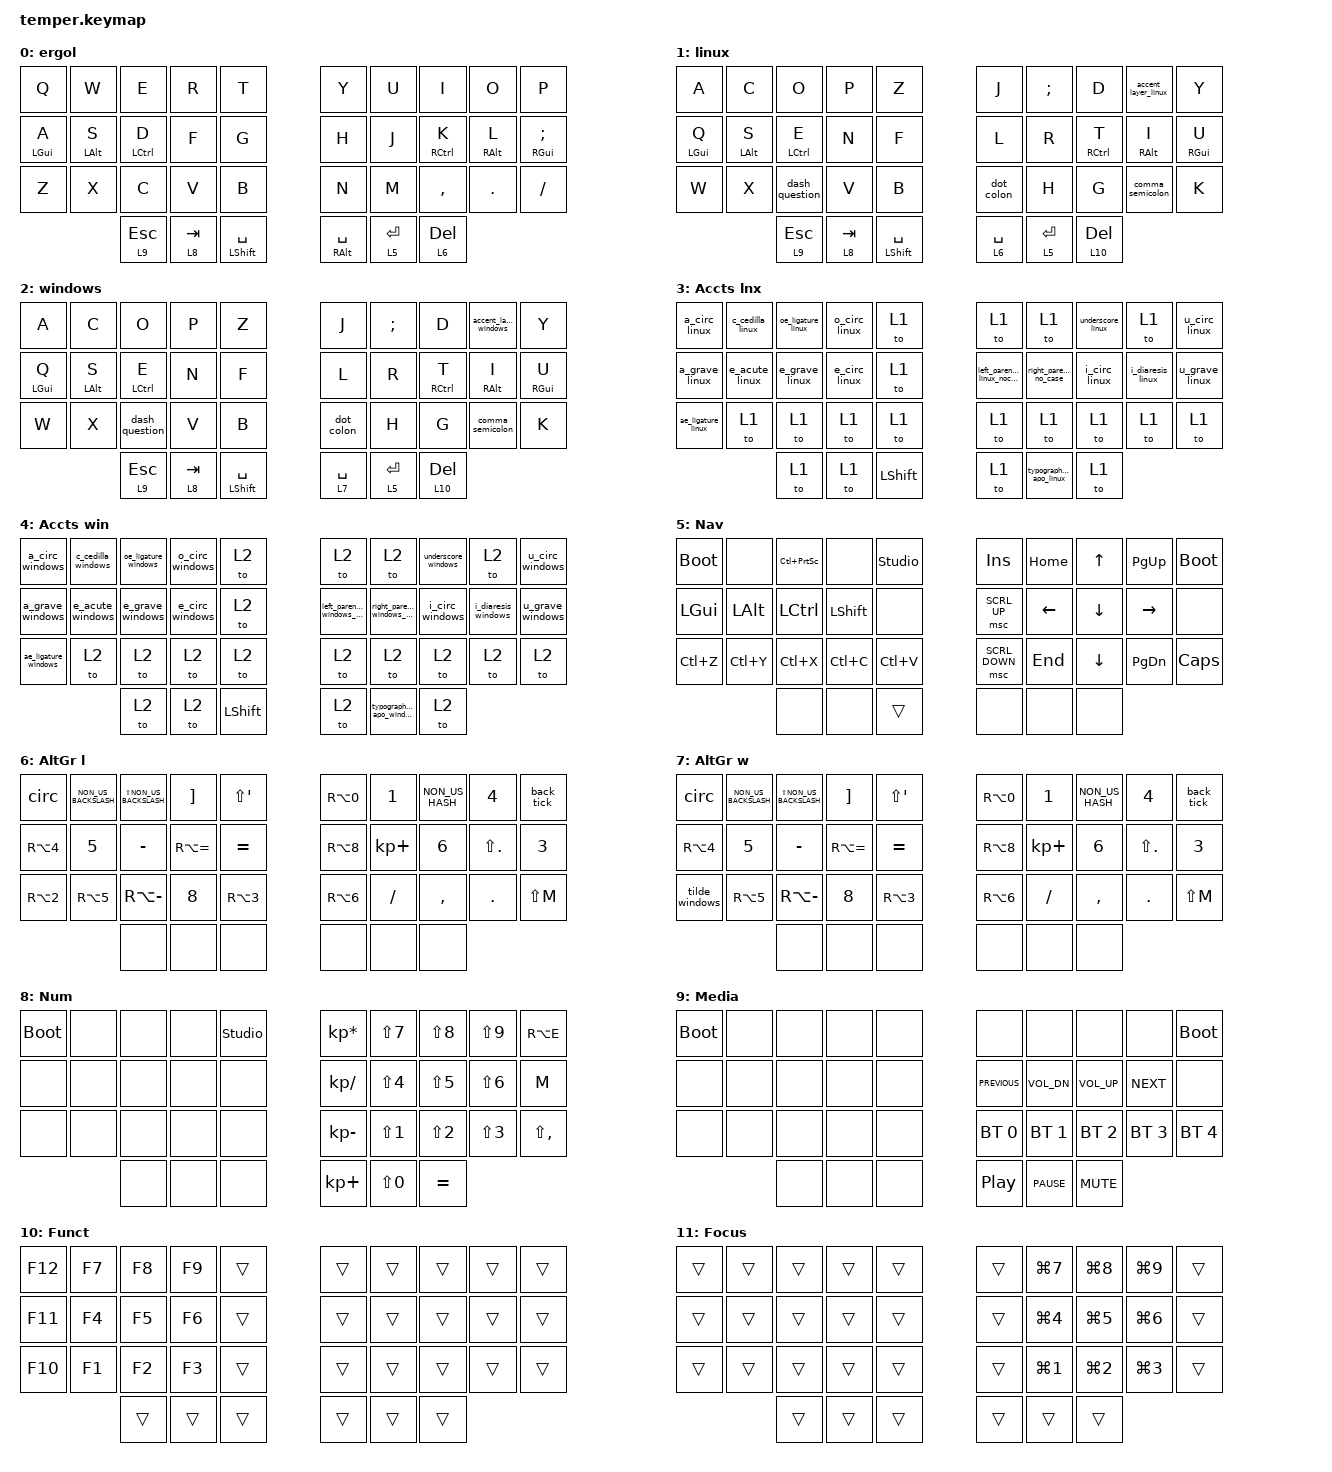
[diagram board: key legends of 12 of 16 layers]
/*
 * Copyright (c) 2020 duckyb
 *
 * SPDX-License-Identifier: MIT
 */

#include <dt-bindings/zmk/mouse.h>
#include <input/processors.dtsi>

#define ZMK_POINTING_DEFAULT_MOVE_VAL 1800  // 600, 1200
#define ZMK_MOUSE_DEFAULT_SCRL_VAL 20    // 10

#include <behaviors.dtsi>
#include <dt-bindings/zmk/bt.h>
#include <dt-bindings/zmk/keys.h>
#include <dt-bindings/zmk/pointing.h>

&mmv_input_listener {
    precisionnav {
        layers = <1>;
        input-processors = <&zip_xy_scaler 1 3>;
    };

    precisionnum {
        layers = <2>;
        input-processors = <&zip_xy_scaler 1 2>;
    };
};

&mt {
    tapping-term-ms = <150>;
    flavor = "balanced";
};

&lt { tapping-term-ms = <165>; };

/ {
    behaviors {
        mmv {
            acceleration-exponent = <2>; // 1
            time-to-max-speed-ms = <40>; // 40
            delay-ms = <0>; // 0
        };

        hm: hm {
            compatible = "zmk,behavior-hold-tap";
            label = "HM";
            bindings = <&kp>, <&kp>;

            #binding-cells = <2>;
            quick-tap-ms = <175>;
            tapping-term-ms = <280>;
            global-quick-tap;
            flavor = "balanced";
        };

        hml: hml {
            compatible = "zmk,behavior-hold-tap";
            label = "HML";
            bindings = <&kp>, <&kp>;

            #binding-cells = <2>;
            tapping-term-ms = <280>;
            quick-tap-ms = <175>;
            flavor = "balanced";
            hold-trigger-key-positions = <0 1 2 3 4 20 21 22 23 24 14 25 15 5 6 16 26 27 17 7 8 18 28 29 19 9 11 12 13>;
            require-prior-idle-ms = <150>;
            hold-trigger-on-release;
        };

        hmr: hmr {
            compatible = "zmk,behavior-hold-tap";
            label = "HMR";
            bindings = <&kp>, <&kp>;

            #binding-cells = <2>;
            tapping-term-ms = <280>;
            quick-tap-ms = <175>;
            flavor = "balanced";
            hold-trigger-key-positions = <0 10 20 21 1 11 12 2 3 4 24 14 13 23 22 25 26 28 27 29 9 8 7 6 5 15 16 17 18 30 31 32 33 34 35>;
            require-prior-idle-ms = <150>;
            hold-trigger-on-release;
        };

        mo_tog: mo_tog {
            compatible = "zmk,behavior-hold-tap";
            label = "MO_TOG";
            bindings = <&mo>, <&tog>;

            #binding-cells = <2>;
            tapping-term-ms = <200>;
            quick-tap-ms = <180>;
        };

        space_alt: space_alt {
            compatible = "zmk,behavior-hold-tap";
            label = "SPACE_ALT";
            bindings = <&kp>, <&kp>;

            #binding-cells = <2>;
            tapping-term-ms = <235>;
            quick-tap-ms = <100>;
            flavor = "tap-preferred";
            hold-trigger-key-positions = <10 12 20 21 16 17 19 6>;
            hold-trigger-on-release;
        };

        dot_colon: dot_colon {
            compatible = "zmk,behavior-mod-morph";
            label = "DOT_COLON";
            bindings = <&kp LS(COMMA)>, <&kp DOT>;

            #binding-cells = <0>;
            mods = <(MOD_LSFT|MOD_RSFT)>;
        };

        comma_semicolon: comma_semicolon {
            compatible = "zmk,behavior-mod-morph";
            label = "COMMA_SEMICOLON";
            bindings = <&kp M>, <&kp COMMA>;

            #binding-cells = <0>;
            mods = <(MOD_LSFT|MOD_RSFT)>;
        };

        a_circ_linux: a_circ_linux {
            compatible = "zmk,behavior-mod-morph";
            label = "A_CIRC_LINUX";
            bindings = <&a_circ_linux_lower>, <&a_circ_linux_upper>;

            #binding-cells = <0>;
            mods = <(MOD_LSFT|MOD_RSFT)>;
        };

        c_cedilla_linux: c_cedilla_linux {
            compatible = "zmk,behavior-mod-morph";
            label = "C_CEDILLA_LINUX";
            bindings = <&c_cedilla_linux_lower>, <&c_cedilla_linux_upper>;

            #binding-cells = <0>;
            mods = <(MOD_LSFT|MOD_RSFT)>;
        };

        oe_ligature_linux: oe_ligature_linux {
            compatible = "zmk,behavior-mod-morph";
            label = "OE_LIGATURE_LINUX";
            bindings = <&oe_ligature_linux_lower>, <&oe_ligature_linux_upper>;

            #binding-cells = <0>;
            mods = <(MOD_LSFT|MOD_RSFT)>;
        };

        o_circ_linux: o_circ_linux {
            compatible = "zmk,behavior-mod-morph";
            label = "O_CIRC_LINUX";
            bindings = <&o_circ_lower_linux>, <&o_circ_upper_linux>;

            #binding-cells = <0>;
            mods = <(MOD_LSFT|MOD_RSFT)>;
        };

        a_grave_linux: a_grave_linux {
            compatible = "zmk,behavior-mod-morph";
            label = "A_GRAVE_LINUX";
            bindings = <&a_grave_lower_linux>, <&a_grave_upper_linux>;

            #binding-cells = <0>;
            mods = <(MOD_LSFT|MOD_RSFT)>;
        };

        e_acute_linux: e_acute_linux {
            compatible = "zmk,behavior-mod-morph";
            label = "E_ACUTE_LINUX";
            bindings = <&e_acute_lower_linux>, <&e_acute_upper_linux>;

            #binding-cells = <0>;
            mods = <(MOD_LSFT|MOD_RSFT)>;
        };

        e_grave_linux: e_grave_linux {
            compatible = "zmk,behavior-mod-morph";
            label = "E_GRAVE_LINUX";
            bindings = <&e_grave_lower_linux>, <&e_grave_upper_linux>;

            #binding-cells = <0>;
            mods = <(MOD_LSFT|MOD_RSFT)>;
        };

        e_circ_linux: e_circ_linux {
            compatible = "zmk,behavior-mod-morph";
            label = "E_CIRC_LINUX";
            bindings = <&e_circ_lower_linux>, <&e_circ_upper_linux>;

            #binding-cells = <0>;
            mods = <(MOD_LSFT|MOD_RSFT)>;
        };

        o_circ_windows: o_circ_windows {
            compatible = "zmk,behavior-mod-morph";
            label = "O_CIRC_WINDOWS";
            bindings = <&o_circ_lower_windows>, <&o_circ_upper_windows>;

            #binding-cells = <0>;
            mods = <(MOD_LSFT|MOD_RSFT)>;
        };

        dash_question: dash_question {
            compatible = "zmk,behavior-mod-morph";
            label = "DASH_QUESTION";
            bindings = <&kp NUMBER_6>, <&kp LS(M)>;

            #binding-cells = <0>;
            mods = <(MOD_LSFT|MOD_RSFT)>;
        };

        a_circ_windows: a_circ_windows {
            compatible = "zmk,behavior-mod-morph";
            label = "A_CIRC_WINDOWS";
            bindings = <&a_circ_windows_lower>, <&a_circ_windows_upper>;

            #binding-cells = <0>;
            mods = <(MOD_LSFT|MOD_RSFT)>;
        };

        c_cedilla_windows: c_cedilla_windows {
            compatible = "zmk,behavior-mod-morph";
            label = "C_CEDILLA_WINDOWS";
            bindings = <&c_cedila_lower_windows>, <&c_cedilla_upper_windows>;

            #binding-cells = <0>;
            mods = <(MOD_LSFT|MOD_RSFT)>;
        };

        a_grave_windows: a_grave_windows {
            compatible = "zmk,behavior-mod-morph";
            label = "A_GRAVE_WINDOWS";
            bindings = <&a_grave_lower_windows>, <&a_grave_upper_windows>;

            #binding-cells = <0>;
            mods = <(MOD_LSFT|MOD_RSFT)>;
        };

        e_acute_windows: e_acute_windows {
            compatible = "zmk,behavior-mod-morph";
            label = "E_ACUTE_WINDOWS";
            bindings = <&e_acute_lower_windows>, <&e_acute_upper_windows>;

            #binding-cells = <0>;
            mods = <(MOD_LSFT|MOD_RSFT)>;
        };

        e_grave_windows: e_grave_windows {
            compatible = "zmk,behavior-mod-morph";
            label = "E_GRAVE_WINDOWS";
            bindings = <&e_grave_lower_windows>, <&e_grave_upper_windows>;

            #binding-cells = <0>;
            mods = <(MOD_LSFT|MOD_RSFT)>;
        };

        u_grave_windows: u_grave_windows {
            compatible = "zmk,behavior-mod-morph";
            label = "U_GRAVE_WINDOWS";
            bindings = <&u_grave_lower_windows>, <&u_grave_upper_windows>;

            #binding-cells = <0>;
            mods = <(MOD_LSFT|MOD_RSFT)>;
        };

        accent_layer_linux: accent_layer_linux {
            compatible = "zmk,behavior-mod-morph";
            label = "ACCENT_LAYER_LINUX";
            bindings = <&to 3>, <&kp SLASH>;

            #binding-cells = <0>;
            mods = <(MOD_LSFT|MOD_RSFT)>;
        };

        accent_layer_windows: accent_layer_windows {
            compatible = "zmk,behavior-mod-morph";
            label = "ACCENT_LAYER_WINDOWS";
            bindings = <&to 4>, <&kp SLASH>;

            #binding-cells = <0>;
            mods = <(MOD_LSFT|MOD_RSFT)>;
        };

        ae_ligature_linux: ae_ligature_linux {
            compatible = "zmk,behavior-mod-morph";
            label = "AE_LIGATURE_LINUX";
            bindings = <&ae_ligature_linux_lower>, <&ae_ligature_linux_upper>;

            #binding-cells = <0>;
            mods = <(MOD_LSFT|MOD_RCTL)>;
        };

        u_grave_linux: u_grave_linux {
            compatible = "zmk,behavior-mod-morph";
            label = "U_GRAVE_LINUX";
            bindings = <&u_grave_lower_linux>, <&u_grave_upper_linux>;

            #binding-cells = <0>;
            mods = <(MOD_LSFT|MOD_RSFT)>;
        };

        u_circ_linux: u_circ_linux {
            compatible = "zmk,behavior-mod-morph";
            label = "U_CIRC_LINUX";
            bindings = <&u_circ_lower_linux>, <&u_circ_upper_linux>;

            #binding-cells = <0>;
            mods = <(MOD_LSFT|MOD_RSFT)>;
        };

        left_parenthesis_linux_nocase: left_parenthesis_linux_nocase {
            compatible = "zmk,behavior-mod-morph";
            label = "LEFT_PARENTHESIS_LINUX_NOCASE";
            bindings = <&left_parenthesis_linux>, <&left_parenthesis_linux>;

            #binding-cells = <0>;
            mods = <(MOD_LSFT|MOD_RSFT)>;
        };

        right_parenthesis_no_case: right_parenthesis_no_case {
            compatible = "zmk,behavior-mod-morph";
            label = "RIGHT_PARENTHESIS_NO_CASE";
            bindings = <&right_parenthesis_linux>, <&right_parenthesis_linux>;

            #binding-cells = <0>;
            mods = <(MOD_LSFT|MOD_RSFT)>;
        };

        i_circ_linux: i_circ_linux {
            compatible = "zmk,behavior-mod-morph";
            label = "I_CIRC_LINUX";
            bindings = <&i_circ_lower_linux>, <&i_circ_upper_linux>;

            #binding-cells = <0>;
            mods = <(MOD_LSFT|MOD_RSFT)>;
        };

        i_diaresis_linux: i_diaresis_linux {
            compatible = "zmk,behavior-mod-morph";
            label = "I_DIARESIS_LINUX";
            bindings = <&i_diaresis_lower_linux>, <&i_diaresis_upper_linux>;

            #binding-cells = <0>;
            mods = <(MOD_LSFT|MOD_RSFT)>;
        };

        u_circ_windows: u_circ_windows {
            compatible = "zmk,behavior-mod-morph";
            label = "U_CIRC_WINDOWS";
            bindings = <&u_circ_lower_windows>, <&u_circ_upper_windows>;

            #binding-cells = <0>;
            mods = <(MOD_LSFT|MOD_RSFT)>;
        };

        i_diaresis_windows: i_diaresis_windows {
            compatible = "zmk,behavior-mod-morph";
            label = "I_DIARESIS_WINDOWS";
            bindings = <&i_diaresis_lower_windows>, <&i_diaresis_upper_windows>;

            #binding-cells = <0>;
            mods = <(MOD_LSFT|MOD_RSFT)>;
        };

        i_circ_windows: i_circ_windows {
            compatible = "zmk,behavior-mod-morph";
            label = "I_CIRC_WINDOWS";
            bindings = <&i_circ_lower_windows>, <&i_circ_upper_windows>;

            #binding-cells = <0>;
            mods = <(MOD_LSFT|MOD_RSFT)>;
        };

        left_parenthesis_windows_nocase: left_parenthesis_windows_nocase {
            compatible = "zmk,behavior-mod-morph";
            label = "LEFT_PARENTHESIS_WINDOWS_NOCASE";
            bindings = <&left_parenthesis_windows>, <&left_parenthesis_windows>;

            #binding-cells = <0>;
            mods = <(MOD_LSFT|MOD_RSFT)>;
        };

        right_parenthesis_windows_nocas: right_parenthesis_windows_nocas {
            compatible = "zmk,behavior-mod-morph";
            label = "RIGHT_PARENTHESIS_WINDOWS_NOCAS";
            bindings =
                <&right_parenthesis_windows>,
                <&right_parenthesis_windows>;

            #binding-cells = <0>;
            mods = <(MOD_LSFT|MOD_RSFT)>;
        };

        oe_ligature_windows: oe_ligature_windows {
            compatible = "zmk,behavior-mod-morph";
            label = "OE_LIGATURE_WINDOWS";
            bindings =
                <&oe_ligature_windows_lower>,
                <&oe_ligature_upper_windows>;

            #binding-cells = <0>;
            mods = <(MOD_LSFT|MOD_RSFT)>;
        };

        e_circ_windows: e_circ_windows {
            compatible = "zmk,behavior-mod-morph";
            label = "E_CIRC_WINDOWS";
            bindings = <&e_circ_lower_windows>, <&e_circ_upper_windows>;

            #binding-cells = <0>;
            mods = <(MOD_LSFT|MOD_RSFT)>;
        };

        ae_ligature_windows: ae_ligature_windows {
            compatible = "zmk,behavior-mod-morph";
            label = "AE_LIGATURE_WINDOWS";
            bindings =
                <&ae_ligature_windows_lower>,
                <&ae_ligature_upper_windows>;

            #binding-cells = <0>;
            mods = <(MOD_LSFT|MOD_RSFT)>;
        };
    };

    combos {
        compatible = "zmk,combos";

        Cut {
            bindings = <&kp LC(X)>;
            key-positions = <21 22>;
            layers = <1 0 2>;
        };

        Copy {
            bindings = <&kp LC(C)>;
            key-positions = <22 23>;
            layers = <1>;
        };

        Paste {
            bindings = <&kp LC(V)>;
            key-positions = <23 24>;
            layers = <1>;
        };

        screenshot {
            bindings = <&kp LC(PRINTSCREEN)>;
            key-positions = <9 8>;
            layers = <1 0 2>;
        };

        boot_l {
            bindings = <&bootloader>;
            key-positions = <0 4 32>;
            layers = <1>;
        };

        win_nav_left {
            bindings = <&kp LG(LEFT)>;
            key-positions = <16 17>;
            layers = <11>;
        };

        win_nav_right {
            bindings = <&kp LG(RIGHT)>;
            key-positions = <19 18>;
            layers = <11>;
        };

        win_nav_up {
            bindings = <&kp LG(UP_ARROW)>;
            key-positions = <7 8>;
            layers = <11>;
        };

        win_nav_down {
            bindings = <&kp LG(DOWN_ARROW)>;
            key-positions = <17 18>;
            layers = <11>;
        };

        win_nav_left_shift {
            bindings = <&kp LG(LS(LEFT))>;
            key-positions = <16 17 18>;
            layers = <11>;
        };

        win_nav_right_shift {
            bindings = <&kp LG(LS(RIGHT))>;
            key-positions = <19 18 17>;
            layers = <11>;
        };

        mouse_layer_switch {
            bindings = <&tog 12>;
            key-positions = <14 15>;
            timeout-ms = <175>;
        };

        linux_to_windows {
            bindings = <&to 2>;
            key-positions = <34 35>;
            layers = <1>;
        };

        windows_to_ergol {
            bindings = <&to 0>;
            key-positions = <34 35>;
            layers = <2>;
        };

        ergol_to_linux {
            bindings = <&to 1>;
            key-positions = <34 35>;
            layers = <0>;
        };

        windows_focus {
            bindings = <&mo 11>;
            key-positions = <31 32>;
            layers = <2 1 0>;
        };

        paste_with_mouse {
            bindings = <&shift_right_click>;
            key-positions = <5 6>;
        };

        backspace_combo {
            bindings = <&kp BACKSPACE>;
            key-positions = <6 7>;
            layers = <0 2 1>;
        };

        Tmux_layer {
            bindings = <&mo 13>;
            key-positions = <30 31>;
        };

        vi_layer {
            bindings = <&mo 15>;
            key-positions = <30 32>;
            layers = <0 2 1>;
        };
    };

    macros {
        a_circ_linux_lower: a_circ_linux_lower {
            compatible = "zmk,behavior-macro";
            #binding-cells = <0>;
            bindings = <&kp RA(Q) &to 1>;
            label = "A_CIRC_LINUX_LOWER";
        };

        a_circ_linux_upper: a_circ_linux_upper {
            compatible = "zmk,behavior-macro";
            #binding-cells = <0>;
            bindings = <&kp RA(A) &to 1>;
            label = "A_CIRC_LINUX_UPPER";
        };

        c_cedilla_linux_lower: c_cedilla_linux_lower {
            compatible = "zmk,behavior-macro";
            #binding-cells = <0>;
            bindings = <&kp RA(R) &to 1>;
            label = "C_CEDILLA_LINUX_LOWER";
        };

        c_cedilla_linux_upper: c_cedilla_linux_upper {
            compatible = "zmk,behavior-macro";
            #binding-cells = <0>;
            bindings = <&kp RA(LS(R)) &to 1>;
            label = "C_CEDILLA_LINUX_UPPER";
        };

        oe_ligature_linux_lower: oe_ligature_linux {
            compatible = "zmk,behavior-macro";
            #binding-cells = <0>;
            bindings = <&kp GRAVE &to 1>;
            label = "OE_LIGATURE_LINUX_LOWER";
        };

        oe_ligature_linux_upper: oe_ligature_linux_upper {
            compatible = "zmk,behavior-macro";
            #binding-cells = <0>;
            bindings = <&kp LS(GRAVE) &to 1>;
            label = "OE_LIGATURE_LINUX_UPPER";
        };

        o_circ_lower_linux: o_circ_lower_linux {
            compatible = "zmk,behavior-macro";
            #binding-cells = <0>;
            bindings = <&kp LEFT_BRACKET &kp O &to 1>;
            label = "O_CIRC_LOWER_LINUX";
        };

        o_circ_upper_linux: o_circ_upper_linux {
            compatible = "zmk,behavior-macro";
            #binding-cells = <0>;
            bindings = <&kp LEFT_BRACKET &kp LS(O) &to 1>;
            label = "O_CIRC_UPPER_LINUX";
        };

        a_grave_lower_linux: a_grave_lower_linux {
            compatible = "zmk,behavior-macro";
            #binding-cells = <0>;
            bindings = <&kp N0 &to 1>;
            label = "A_GRAVE_LOWER_LINUX";
        };

        a_grave_upper_linux: a_grave_upper_linux {
            compatible = "zmk,behavior-macro";
            #binding-cells = <0>;
            bindings = <&kp RA(N7) &kp LS(Q) &to 1>;
            label = "A_GRAVE_UPPER_LINUX";
        };

        e_acute_lower_linux: e_acute_lower_linux {
            compatible = "zmk,behavior-macro";
            #binding-cells = <0>;
            bindings = <&kp NUMBER_2 &to 1>;
            label = "E_ACUTE_LOWER_LINUX";
        };

        e_acute_upper_linux: e_acute_upper_linux {
            compatible = "zmk,behavior-macro";
            #binding-cells = <0>;
            bindings = <&kp LC(LS(U)) &kp N0 &kp N0 &kp C &kp N9 &kp ENTER &to 1>;
            label = "E_ACUTE_UPPER_LINUX";
        };

        e_grave_lower_linux: e_grave_lower_linux {
            compatible = "zmk,behavior-macro";
            #binding-cells = <0>;
            bindings = <&kp NUMBER_7 &to 1>;
            label = "E_GRAVE_LOWER_LINUX";
        };

        e_grave_upper_linux: e_grave_upper_linux {
            compatible = "zmk,behavior-macro";
            #binding-cells = <0>;
            bindings = <&kp RA(RS(NUMBER_7)) &to 1>;
            label = "E_GRAVE_UPPER_LINUX";
        };

        e_circ_lower_linux: e_circ_lower_linux {
            compatible = "zmk,behavior-macro";
            #binding-cells = <0>;
            bindings = <&kp RA(RIGHT_BRACKET) &to 1>;
            label = "E_CIRC_LOWER_LINUX";
        };

        e_circ_upper_linux: e_circ_upper_linux {
            compatible = "zmk,behavior-macro";
            #binding-cells = <0>;
            bindings = <&kp RA(D) &to 1>;
            label = "E_CIRC_UPPER_LINUX";
        };

        a_circ_windows_lower: a_circ {
            compatible = "zmk,behavior-macro";
            #binding-cells = <0>;
            bindings = <&kp LEFT_BRACKET &kp Q &to 2>;
            label = "A_CIRC";
        };

        o_circ_lower_windows: o_circ {
            compatible = "zmk,behavior-macro";
            #binding-cells = <0>;
            bindings = <&kp LEFT_BRACKET &kp O &to 2>;
            label = "O_CIRC";
        };

        e_circ_lower_windows: e_circ_lower_windows {
            compatible = "zmk,behavior-macro";
            #binding-cells = <0>;
            bindings = <&kp LEFT_BRACKET &kp E &to 2>;
            label = "E_CIRC_LOWER_WINDOWS";
        };

        ae_ligature_linux_lower: ae_ligature {
            compatible = "zmk,behavior-macro";
            #binding-cells = <0>;
            bindings = <&kp RA(G) &to 1>;
            label = "AE_LIGATURE";
        };

        i_circ_lower_windows: i_circ {
            compatible = "zmk,behavior-macro";
            #binding-cells = <0>;
            bindings = <&kp LEFT_BRACKET &kp I &to 2>;
            label = "I_CIRC";
        };

        i_diaresis_lower_windows: i_diaresis {
            compatible = "zmk,behavior-macro";
            #binding-cells = <0>;
            bindings = <&kp LS(LEFT_BRACKET) &kp I &to 2>;
            label = "I_DIARESIS";
        };

        u_circ_lower_windows: u_circ {
            compatible = "zmk,behavior-macro";
            #binding-cells = <0>;
            bindings = <&kp LEFT_BRACKET &kp U &to 2>;
            label = "U_CIRC";
        };

        o_circ_upper_windows: o_circ_maj {
            compatible = "zmk,behavior-macro";
            #binding-cells = <0>;
            bindings = <&kp LEFT_BRACKET &kp LS(O) &to 2>;
            label = "O_CIRC_MAJ";
        };

        circ: circ {
            compatible = "zmk,behavior-macro";
            #binding-cells = <0>;
            bindings = <&kp RA(N9)>;
            label = "CIRC";
        };

        back_tick: back_tick {
            compatible = "zmk,behavior-macro";
            #binding-cells = <0>;
            bindings = <&kp RA(N7) &kp SPACE>;
            label = "BACK_TICK";
        };

        oe_ligature_windows_lower: oe_ligature_windows {
            compatible = "zmk,behavior-macro";
            #binding-cells = <0>;
            bindings = <&kt LEFT_ALT &kp KP_NUMBER_0 &kp KP_N1 &kp KP_N5 &kp KP_N6 &kt LEFT_ALT &to 2>;
            label = "OE_LIGATURE_WINDOWS";
        };

        tilde_windows: tilde_windows {
            compatible = "zmk,behavior-macro";
            #binding-cells = <0>;
            bindings = <&kp RA(NUMBER_2) &kp SPACE>;
            label = "TILDE_WINDOWS";
        };

        ae_ligature_windows_lower: ae_ligature_windows_lower {
            compatible = "zmk,behavior-macro";
            #binding-cells = <0>;
            bindings = <&kt LEFT_ALT &kp KP_N0 &kp KP_N2 &kp KP_N3 &kp KP_N0 &kt LEFT_ALT &to 2>;
            label = "AE_LIGATURE_WINDOWS_LOWER";
        };

        a_circ_windows_upper: a_circ_windows_maj {
            compatible = "zmk,behavior-macro";
            #binding-cells = <0>;
            bindings = <&kp LEFT_BRACKET &kp LS(Q) &to 2>;
            label = "A_CIRC_WINDOWS_MAJ";
        };

        c_cedilla_upper_windows: c_cedilla_maj_windows {
            compatible = "zmk,behavior-macro";
            #binding-cells = <0>;
            bindings = <&kt LEFT_ALT &kp KP_N0 &kp KP_N1 &kp KP_N9 &kp KP_N9 &kt LEFT_ALT &to 2>;
            label = "C_CEDILLA_MAJ_WINDOWS";
        };

        a_grave_lower_windows: a_grave_lower_windows {
            compatible = "zmk,behavior-macro";
            #binding-cells = <0>;
            bindings = <&kp N0 &to 2>;
            label = "A_GRAVE_LOWER_WINDOWS";
        };

        e_acute_upper_windows: e_acute_upper_windows {
            compatible = "zmk,behavior-macro";
            #binding-cells = <0>;
            bindings = <&kt LEFT_ALT &kp KP_N0 &kp KP_N2 &kp KP_N0 &kp KP_N1 &kt LEFT_ALT &to 2>;
            label = "E_ACUTE_UPPER_WINDOWS";
        };

        e_grave_upper_windows: e_grave_upper_windows {
            compatible = "zmk,behavior-macro";
            #binding-cells = <0>;
            bindings = <&kp RA(N7) &kp LS(E) &to 2>;
            label = "E_GRAVE_UPPER_WINDOWS";
        };

        u_grave_upper_windows: u_grave_upper_windows {
            compatible = "zmk,behavior-macro";
            #binding-cells = <0>;
            bindings = <&kp RA(N7) &kp LS(U) &to 2>;
            label = "U_GRAVE_UPPER_WINDOWS";
        };

        typographical_apo_linux: typographical_apo_linux {
            compatible = "zmk,behavior-macro";
            #binding-cells = <0>;
            bindings = <&kp LS(LC(U)) &kp KP_N2 &kp KP_N0 &kp KP_N1 &kp KP_N9 &kp ENTER &to 1>;
            label = "TYPOGRAPHICAL_APO_LINUX";
        };

        typographical_apo_windows: typographical_apo_windows {
            compatible = "zmk,behavior-macro";
            #binding-cells = <0>;
            bindings = <&kt LEFT_ALT &kp KP_N0 &kp KP_N1 &kp KP_N4 &kp KP_N6 &kt LEFT_ALT &to 2>;
            label = "TYPOGRAPHICAL_APO_WINDOWS";
        };

        ae_ligature_linux_upper: ae_ligature_upper_linux {
            compatible = "zmk,behavior-macro";
            #binding-cells = <0>;
            bindings = <&kp RA(G) &to 1>;
            label = "AE_LIGATURE_UPPER_LINUX";
        };

        underscore_linux: underscore_linux {
            compatible = "zmk,behavior-macro";
            #binding-cells = <0>;
            bindings = <&kp N8 &to 1>;
            label = "UNDERSCORE_LINUX";
        };

        u_grave_upper_linux: u_grave_upper_linux {
            compatible = "zmk,behavior-macro";
            #binding-cells = <0>;
            bindings = <&kp RA(N7) &kp LS(U) &to 1>;
            label = "U_GRAVE_UPPER_LINUX";
        };

        u_grave_lower_linux: u_grave_lower_linux {
            compatible = "zmk,behavior-macro";
            #binding-cells = <0>;
            bindings = <&kp RA(N7) &kp U &to 1>;
            label = "U_GRAVE_LOWER_LINUX";
        };

        u_circ_lower_linux: u_circ_linux_lower {
            compatible = "zmk,behavior-macro";
            #binding-cells = <0>;
            bindings = <&kp LEFT_BRACKET &kp U &to 1>;
            label = "U_CIRC_LINUX_LOWER";
        };

        u_circ_upper_linux: u_circ_upper_linux {
            compatible = "zmk,behavior-macro";
            #binding-cells = <0>;
            bindings = <&kp LEFT_BRACKET &kp LS(U) &to 1>;
            label = "U_CIRC_UPPER_LINUX";
        };

        left_parenthesis_linux: left_parenthesis_linux {
            compatible = "zmk,behavior-macro";
            #binding-cells = <0>;
            bindings = <&kp N5 &to 1>;
            label = "LEFT_PARENTHESIS_LINUX";
        };

        right_parenthesis_linux: right_parenthesis_linux {
            compatible = "zmk,behavior-macro";
            #binding-cells = <0>;
            bindings = <&kp MINUS &to 1>;
            label = "RIGHT_PARENTHESIS_LINUX";
        };

        i_circ_lower_linux: i_circ_lower_linux {
            compatible = "zmk,behavior-macro";
            #binding-cells = <0>;
            bindings = <&kp LEFT_BRACKET &kp I &to 1>;
            label = "I_CIRC_LOWER_LINUX";
        };

        i_circ_upper_linux: i_circ_upper_linux {
            compatible = "zmk,behavior-macro";
            #binding-cells = <0>;
            bindings = <&kp LEFT_BRACKET &kp LS(I) &to 1>;
            label = "I_CIRC_UPPER_LINUX";
        };

        i_diaresis_lower_linux: i_diaresis_lower_linux {
            compatible = "zmk,behavior-macro";
            #binding-cells = <0>;
            bindings = <&kp LS(LEFT_BRACKET) &kp I &to 1>;
            label = "I_DIARESIS_LOWER_LINUX";
        };

        i_diaresis_upper_linux: i_diaresis_upper_linux {
            compatible = "zmk,behavior-macro";
            #binding-cells = <0>;
            bindings = <&kp LS(LEFT_BRACKET) &kp LS(I) &to 1>;
            label = "I_DIARESIS_UPPER_LINUX";
        };

        underscore_windows: underscore_windows {
            compatible = "zmk,behavior-macro";
            #binding-cells = <0>;
            bindings = <&kp N8 &to 2>;
            label = "UNDERSCORE_WINDOWS";
        };

        u_circ_upper_windows: u_circ_upper_windows {
            compatible = "zmk,behavior-macro";
            #binding-cells = <0>;
            bindings = <&kp LEFT_BRACKET &kp LS(U) &to 2>;
            label = "U_CIRC_UPPER_WINDOWS";
        };

        u_grave_lower_windows: u_grave_lower_windows {
            compatible = "zmk,behavior-macro";
            #binding-cells = <0>;
            bindings = <&kp RA(N7) &kp U &to 2>;
            label = "U_GRAVE_LOWER_WINDOWS";
        };

        i_diaresis_upper_windows: i_diaresis_upper_windows {
            compatible = "zmk,behavior-macro";
            #binding-cells = <0>;
            bindings = <&kp LS(LEFT_BRACKET) &kp LS(I) &to 2>;
            label = "I_DIARESIS_UPPER_WINDOWS";
        };

        i_circ_upper_windows: i_circ_upper_windows {
            compatible = "zmk,behavior-macro";
            #binding-cells = <0>;
            bindings = <&kp LEFT_BRACKET &kp LS(I) &to 2>;
            label = "I_CIRC_UPPER_WINDOWS";
        };

        left_parenthesis_windows: left_parenthesis_windows {
            compatible = "zmk,behavior-macro";
            #binding-cells = <0>;
            bindings = <&kp N5 &to 2>;
            label = "LEFT_PARENTHESIS_WINDOWS";
        };

        right_parenthesis_windows: right_parenthesis_windows {
            compatible = "zmk,behavior-macro";
            #binding-cells = <0>;
            bindings = <&kp MINUS &to 2>;
            label = "RIGHT_PARENTHESIS_WINDOWS";
        };

        oe_ligature_upper_windows: oe_ligature_upper_windows {
            compatible = "zmk,behavior-macro";
            #binding-cells = <0>;
            bindings = <&kt LEFT_ALT &kp KP_NUMBER_0 &kp KP_N1 &kp KP_N4 &kp KP_N0 &kt LEFT_ALT &to 2>;
            label = "OE_LIGATURE_UPPER_WINDOWS";
        };

        c_cedila_lower_windows: c_cedila_lower_windows {
            compatible = "zmk,behavior-macro";
            #binding-cells = <0>;
            bindings = <&kp N9 &to 2>;
            label = "C_CEDILA_LOWER_WINDOWS";
        };

        a_grave_upper_windows: a_grave_upper_windows {
            compatible = "zmk,behavior-macro";
            #binding-cells = <0>;
            bindings = <&kp RA(N7) &kp LS(Q) &to 2>;
            label = "A_GRAVE_UPPER_WINDOWS";
        };

        e_acute_lower_windows: e_acute_lower_windows {
            compatible = "zmk,behavior-macro";
            #binding-cells = <0>;
            bindings = <&kp N2 &to 2>;
            label = "E_ACUTE_LOWER_WINDOWS";
        };

        e_grave_lower_windows: e_grave_lower_windows {
            compatible = "zmk,behavior-macro";
            #binding-cells = <0>;
            bindings = <&kp N7 &to 2>;
            label = "E_GRAVE_LOWER_WINDOWS";
        };

        e_circ_upper_windows: e_circ_upper_windows {
            compatible = "zmk,behavior-macro";
            #binding-cells = <0>;
            bindings = <&kp LEFT_BRACKET &kp LS(E) &to 2>;
            label = "E_CIRC_UPPER_WINDOWS";
        };

        ae_ligature_upper_windows: ae_ligature_upper_windows {
            compatible = "zmk,behavior-macro";
            #binding-cells = <0>;
            bindings = <&kt LEFT_ALT &kp KP_N0 &kp KP_N1 &kp KP_N9 &kp KP_N8 &kt LEFT_ALT &to 2>;
            label = "AE_LIGATURE_UPPER_WINDOWS";
        };

        shift_right_click: shift_right_click {
            compatible = "zmk,behavior-macro";
            #binding-cells = <0>;
            bindings = <&kt LEFT_SHIFT &mkp RCLK &kt LEFT_SHIFT>;
            label = "SHIFT_RIGHT_CLICK";
        };

        tmux_new_pane: tmux_new_pane {
            compatible = "zmk,behavior-macro";
            #binding-cells = <0>;
            bindings = <&kp LC(B) &kp C>;
            label = "TMUX_NEW_PANE";
        };

        tmux_vsplit: tmux_vsplit {
            compatible = "zmk,behavior-macro";
            #binding-cells = <0>;
            bindings = <&kp LC(B) &kp LS(APOSTROPHE)>;
            label = "TMUX_VSPLIT";
        };

        tmux_hsplit: tmux_hsplit {
            compatible = "zmk,behavior-macro";
            #binding-cells = <0>;
            bindings = <&kp LC(B) &kp NUMBER_3>;
            label = "TMUX_HSPLIT";
        };

        tmux_pane_left: tmux_pane_left {
            compatible = "zmk,behavior-macro";
            #binding-cells = <0>;
            bindings = <&kp LC(B) &kp LEFT_ARROW>;
            label = "TMUX_PANE_LEFT";
        };

        tmux_pane_right: tmux_pane_right {
            compatible = "zmk,behavior-macro";
            #binding-cells = <0>;
            bindings = <&kp LC(B) &kp RIGHT_ARROW>;
            label = "TMUX_PANE_RIGHT";
        };

        tmux_pane_up: tmux_pane_up {
            compatible = "zmk,behavior-macro";
            #binding-cells = <0>;
            bindings = <&kp LC(B) &kp UP_ARROW>;
            label = "TMUX_PANE_UP";
        };

        tmux_pane_down: tmux_pane_down {
            compatible = "zmk,behavior-macro";
            #binding-cells = <0>;
            bindings = <&kp LC(B) &kp DOWN_ARROW>;
            label = "TMUX_PANE_DOWN";
        };

        tmux_pane_zoom: tmux_pane_zoom {
            compatible = "zmk,behavior-macro";
            #binding-cells = <0>;
            bindings = <&kp LC(B) &kp W>;
            label = "TMUX_PANE_ZOOM";
        };

        tmux_pane_close: tmux_pane_close {
            compatible = "zmk,behavior-macro";
            #binding-cells = <0>;
            bindings = <&kp LC(B) &kp X>;
            label = "TMUX_PANE_CLOSE";
        };

        tmux_next_window: tmux_next_window {
            compatible = "zmk,behavior-macro";
            #binding-cells = <0>;
            bindings = <&kp LC(B) &kp N>;
            label = "TMUX_NEXT_WINDOW";
        };

        tmux_prev_window: tmux_prev_window {
            compatible = "zmk,behavior-macro";
            #binding-cells = <0>;
            bindings = <&kp LC(B) &kp P>;
            label = "TMUX_PREV_WINDOW";
        };

        tmux_enter_nav: tmux_enter_nav {
            compatible = "zmk,behavior-macro";
            #binding-cells = <0>;
            bindings = <&kp LC(B) &kp RA(N5) &tog 5>;
            label = "TMUX_ENTER_NAV";
        };

        tmux_quit_nav: tmux_quit_nav {
            compatible = "zmk,behavior-macro";
            #binding-cells = <0>;
            bindings = <&kp ESCAPE &tog 5>;
            label = "TMUX_QUIT_NAV";
        };

        vi_new_tab: vi_new_tab {
            compatible = "zmk,behavior-macro";
            #binding-cells = <0>;
            bindings = <&kp PERIOD &kp T &kp Q &kp B &kp N &kp E &kp Z &kp ENTER>;
            label = "VI_NEW_TAB";
        };

        vi_vsplit: vi_vsplit {
            compatible = "zmk,behavior-macro";
            #binding-cells = <0>;
            bindings = <&kp PERIOD &kp V &kp S &kp P &kp L &kp I &kp T &kp RET>;
            label = "VI_VSPLIT";
        };

        vi_hsplit: vi_hsplit {
            compatible = "zmk,behavior-macro";
            #binding-cells = <0>;
            bindings = <&kp PERIOD &kp S &kp P &kp L &kp I &kp T &kp RET>;
            label = "VI_HSPLIT";
        };

        vi_pane_left: vi_pane_left {
            compatible = "zmk,behavior-macro";
            #binding-cells = <0>;
            bindings = <&kp LC(Z) &kp LEFT_ARROW>;
            label = "VI_PANE_LEFT";
        };

        vi_pane_right: vi_pane_right {
            compatible = "zmk,behavior-macro";
            #binding-cells = <0>;
            bindings = <&kp LC(Z) &kp RIGHT_ARROW>;
            label = "VI_PANE_RIGHT";
        };

        vi_pane_up: vi_pane_up {
            compatible = "zmk,behavior-macro";
            #binding-cells = <0>;
            bindings = <&kp LC(Z) &kp UP_ARROW>;
            label = "VI_PANE_UP";
        };

        vi_pane_down: vi_pane_down {
            compatible = "zmk,behavior-macro";
            #binding-cells = <0>;
            bindings = <&kp LC(Z) &kp DOWN_ARROW>;
            label = "VI_PANE_DOWN";
        };

        vi_pane_close: vi_pane_close {
            compatible = "zmk,behavior-macro";
            #binding-cells = <0>;
            bindings = <&kp PERIOD &kp A &kp ENTER>;
            label = "VI_PANE_CLOSE";
        };

        vi_next_tab: vi_next_tab {
            compatible = "zmk,behavior-macro";
            #binding-cells = <0>;
            bindings = <&kp G &kp T>;
            label = "VI_NEXT_TAB";
        };

        vi_prev_tab: vi_prev_tab {
            compatible = "zmk,behavior-macro";
            #binding-cells = <0>;
            bindings = <&kp G &kp LS(T)>;
            label = "VI_PREV_TAB";
        };
    };

    keymap {
        compatible = "zmk,keymap";

        ergol {
            label = "ergol";
            bindings = <
  &kp Q            &kp W           &kp E               &kp R      &kp T                   &kp Y                &kp U        &kp I                &kp O            &kp P
  &hml LEFT_GUI A  &hm LEFT_ALT S  &hm LEFT_CONTROL D  &kp F      &kp G                   &kp H                &kp J        &hm RIGHT_CONTROL K  &hm RIGHT_ALT L  &hmr RIGHT_GUI SEMICOLON
  &kp Z            &kp X           &kp C               &kp V      &kp B                   &kp N                &kp M        &kp COMMA            &kp PERIOD       &kp SLASH
                                   &lt 9 ESCAPE        &lt 8 TAB  &hm LEFT_SHIFT SPACE    &mt RIGHT_ALT SPACE  &lt 5 ENTER  &lt 6 DEL
            >;
        };

        Basel {
            //            display-name = "Base";

            bindings = <
  &kp A            &kp C           &kp O               &kp P      &kp Z                   &kp J        &kp SEMICOLON  &kp D                &accent_layer_linux  &kp Y
  &hml LEFT_GUI Q  &hm LEFT_ALT S  &hm LEFT_CONTROL E  &kp N      &kp F                   &kp L        &kp R          &hm RIGHT_CONTROL T  &hm RIGHT_ALT I      &hmr RIGHT_GUI U
  &kp W            &kp X           &dash_question      &kp V      &kp B                   &dot_colon   &kp H          &kp G                &comma_semicolon     &kp K
                                   &lt 9 ESCAPE        &lt 8 TAB  &hm LEFT_SHIFT SPACE    &lt 6 SPACE  &lt 5 RETURN   &lt 10 DEL
            >;

            label = "linux";
        };

        Basew {
            label = "windows";

            //            display-name = "Base";

            bindings = <
  &kp A            &kp C           &kp O               &kp P      &kp Z                   &kp J        &kp SEMICOLON  &kp D                &accent_layer_windows  &kp Y
  &hml LEFT_GUI Q  &hm LEFT_ALT S  &hm LEFT_CONTROL E  &kp N      &kp F                   &kp L        &kp R          &hm RIGHT_CONTROL T  &hm RIGHT_ALT I        &hmr RIGHT_GUI U
  &kp W            &kp X           &dash_question      &kp V      &kp B                   &dot_colon   &kp H          &kp G                &comma_semicolon       &kp K
                                   &lt 9 ESCAPE        &lt 8 TAB  &hm LEFT_SHIFT SPACE    &lt 7 SPACE  &lt 5 RETURN   &lt 10 DEL
            >;
        };

        AccentsL {
            bindings = <
  &a_circ_linux       &c_cedilla_linux  &oe_ligature_linux  &o_circ_linux  &to 1             &to 1                           &to 1                       &underscore_linux  &to 1              &u_circ_linux
  &a_grave_linux      &e_acute_linux    &e_grave_linux      &e_circ_linux  &to 1             &left_parenthesis_linux_nocase  &right_parenthesis_no_case  &i_circ_linux      &i_diaresis_linux  &u_grave_linux
  &ae_ligature_linux  &to 1             &to 1               &to 1          &to 1             &to 1                           &to 1                       &to 1              &to 1              &to 1
                                        &to 1               &to 1          &kp LEFT_SHIFT    &to 1                           &typographical_apo_linux    &to 1
            >;

            label = "Accts lnx";
        };

        AccentsW {
            label = "Accts win";
            bindings = <
  &a_circ_windows       &c_cedilla_windows  &oe_ligature_windows  &o_circ_windows  &to 2             &to 2                             &to 2                             &underscore_windows  &to 2                &u_circ_windows
  &a_grave_windows      &e_acute_windows    &e_grave_windows      &e_circ_windows  &to 2             &left_parenthesis_windows_nocase  &right_parenthesis_windows_nocas  &i_circ_windows      &i_diaresis_windows  &u_grave_windows
  &ae_ligature_windows  &to 2               &to 2                 &to 2            &to 2             &to 2                             &to 2                             &to 2                &to 2                &to 2
                                            &to 2                 &to 2            &kp LEFT_SHIFT    &to 2                             &typographical_apo_windows        &to 2
            >;
        };

        Nav {
            bindings = <
  &bootloader   &none         &kp LC(PRINTSCREEN)  &none           &studio_unlock    &kp INS         &kp HOME  &kp UP_ARROW  &kp PAGE_UP    &bootloader
  &kp LEFT_GUI  &kp LEFT_ALT  &kp LCTRL            &kp LEFT_SHIFT  &none             &msc SCRL_UP    &kp LEFT  &kp DOWN      &kp RIGHT      &none
  &kp LC(Z)     &kp LC(Y)     &kp LC(X)            &kp LC(C)       &kp LC(V)         &msc SCRL_DOWN  &kp END   &kp DOWN      &kp PAGE_DOWN  &kp CAPSLOCK
                              &none                &none           &trans            &none           &none     &none
            >;

            label = "Nav";
        };

        AltGrL {
            bindings = <
  &circ             &kp NON_US_BACKSLASH  &kp LS(NON_US_BACKSLASH)  &kp RIGHT_BRACKET  &kp LS(APOS)        &kp RA(N0)        &kp NUMBER_1  &kp NON_US_HASH  &kp NUMBER_4    &back_tick
  &kp RA(NUMBER_4)  &kp N5                &kp MINUS                 &kp RA(EQUAL)      &kp EQUAL           &kp RA(N8)        &kp KP_PLUS   &kp NUMBER_6     &kp LS(PERIOD)  &kp NUMBER_3
  &kp RA(NUMBER_2)  &kp RA(N5)            &kp RA(MINUS)             &kp N8             &kp RA(NUMBER_3)    &kp RA(NUMBER_6)  &kp SLASH     &kp COMMA        &kp DOT         &kp LS(M)
                                          &none                     &none              &none               &none             &none         &none
            >;

            label = "AltGr l";
        };

        AltGrW {
            label = "AltGr w";
            bindings = <
  &circ             &kp NON_US_BACKSLASH  &kp LS(NON_US_BACKSLASH)  &kp RIGHT_BRACKET  &kp LS(APOS)        &kp RA(N0)        &kp NUMBER_1  &kp NON_US_HASH  &kp NUMBER_4  &back_tick
  &kp RA(NUMBER_4)  &kp N5                &kp MINUS                 &kp RA(EQUAL)      &kp EQUAL           &kp RA(N8)        &kp KP_PLUS   &kp NUMBER_6     &kp LS(DOT)   &kp NUMBER_3
  &tilde_windows    &kp RA(N5)            &kp RA(MINUS)             &kp N8             &kp RA(NUMBER_3)    &kp RA(NUMBER_6)  &kp SLASH     &kp COMMA        &kp DOT       &kp LS(M)
                                          &none                     &none              &none               &none             &none         &none
            >;
        };

        Num {
            bindings = <
  &bootloader  &none  &none  &none  &studio_unlock    &kp KP_MULTIPLY  &kp LS(N7)        &kp LS(N8)        &kp LS(N9)        &kp RA(E)
  &none        &none  &none  &none  &none             &kp KP_DIVIDE    &kp LS(NUMBER_4)  &kp LS(N5)        &kp LS(NUMBER_6)  &kp M
  &none        &none  &none  &none  &none             &kp KP_SUBTRACT  &kp LS(NUMBER_1)  &kp LS(NUMBER_2)  &kp LS(NUMBER_3)  &kp LS(COMMA)
                      &none  &none  &none             &kp KP_PLUS      &kp LS(N0)        &kp EQUAL
            >;

            label = "Num";
        };

        Media {
            display-name = "Media";
            bindings = <
  &bootloader  &none  &none  &none  &none    &none             &none         &none            &none         &bootloader
  &none        &none  &none  &none  &none    &kp C_PREVIOUS    &kp C_VOL_DN  &kp C_VOLUME_UP  &kp C_NEXT    &none
  &none        &none  &none  &none  &none    &bt BT_SEL 0      &bt BT_SEL 1  &bt BT_SEL 2     &bt BT_SEL 3  &bt BT_SEL 4
                      &none  &none  &none    &kp C_PLAY_PAUSE  &kp C_PAUSE   &kp C_MUTE
            >;
        };

        Funct {
            bindings = <
  &kp F12  &kp F7  &kp F8  &kp F9  &trans    &trans  &trans  &trans  &trans  &trans
  &kp F11  &kp F4  &kp F5  &kp F6  &trans    &trans  &trans  &trans  &trans  &trans
  &kp F10  &kp F1  &kp F2  &kp F3  &trans    &trans  &trans  &trans  &trans  &trans
                   &trans  &trans  &trans    &trans  &trans  &trans
            >;

            label = "Funct";
        };

        focus_switch {
            bindings = <
  &trans  &trans  &trans  &trans  &trans    &trans  &kp LG(N7)  &kp LG(N8)  &kp LG(N9)  &trans
  &trans  &trans  &trans  &trans  &trans    &trans  &kp LG(N4)  &kp LG(N5)  &kp LG(N6)  &trans
  &trans  &trans  &trans  &trans  &trans    &trans  &kp LG(N1)  &kp LG(N2)  &kp LG(N3)  &trans
                  &trans  &trans  &trans    &trans  &trans      &trans
            >;

            label = "Focus";
        };

        mouse {
            bindings = <
  &none  &none  &none  &none  &none    &msc SCRL_UP    &mkp LCLK       &mmv MOVE_UP    &mkp RCLK        &none
  &none  &none  &none  &none  &none    &none           &mmv MOVE_LEFT  &none           &mmv MOVE_RIGHT  &none
  &none  &none  &none  &none  &none    &msc SCRL_DOWN  &none           &mmv MOVE_DOWN  &none            &none
                &none  &none  &none    &none           &none           &none
            >;

            label = "Mouse";
        };

        Tmux {
            bindings = <
  &none  &none  &none  &none  &none               &tmux_new_pane   &tmux_prev_window  &tmux_pane_up    &tmux_next_window  &none
  &none  &none  &none  &none  &none               &tmux_hsplit     &tmux_pane_left    &tmux_pane_zoom  &tmux_pane_right   &none
  &none  &none  &none  &none  &none               &tmux_vsplit     &none              &tmux_pane_down  &none              &tmux_pane_close
                &none  &none  &kp LEFT_CONTROL    &tmux_enter_nav  &none              &none
            >;

            label = "Tmux";
        };

        tmux_nav {
            bindings = <
  &trans  &trans  &trans  &trans  &trans    &trans          &trans  &trans  &trans  &trans
  &trans  &trans  &trans  &trans  &trans    &trans          &trans  &trans  &trans  &trans
  &trans  &trans  &trans  &trans  &trans    &trans          &trans  &trans  &trans  &trans
                  &trans  &trans  &trans    &tmux_quit_nav  &trans  &trans
            >;

            label = "Tmux_nav";
        };

        vi {
            label = "vi";
            bindings = <
  &none  &none  &none  &none  &none    &vi_new_tab  &vi_prev_tab   &vi_pane_up    &vi_next_tab    &none
  &none  &none  &none  &none  &none    &vi_hsplit   &vi_pane_left  &none          &vi_pane_right  &none
  &none  &none  &none  &none  &none    &vi_vsplit   &none          &vi_pane_down  &none           &vi_pane_close
                &none  &none  &none    &none        &none          &none
            >;
        };
    };

    conditional_layers {
        compatible = "zmk,conditional-layers";

        tmux_nav_cond {
            if-layers = <13 5>;
            then-layer = <14>;
        };
    };
};
